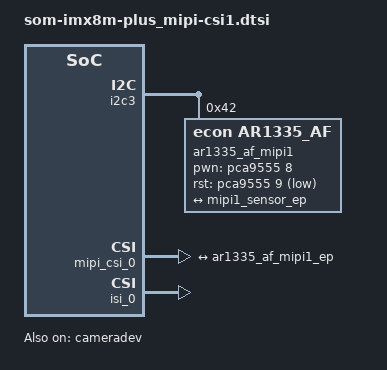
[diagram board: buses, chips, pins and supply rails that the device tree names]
/*
 * Copyright 2022 CompuLab
 */

&i2c3 {
	status = "okay";
	ar1335_af_mipi1: ar1335_af_mipi1@42 {
		compatible = "econ,ar1335_af", "ar1335_af";
		reg = <0x42>;
		pinctrl-names = "default";
		pinctrl-0 = <&pinctrl_csi_mclk>;
		clocks = <&clk IMX8MP_CLK_IPP_DO_CLKO2>;
		clock-names = "csi_mclk";
		assigned-clocks = <&clk IMX8MP_CLK_IPP_DO_CLKO2>;
		assigned-clock-parents = <&clk IMX8MP_CLK_24M>;
		assigned-clock-rates = <24000000>;
		csi_id = <0>;
		pwn-gpios = <&pca9555 8 GPIO_ACTIVE_HIGH>;
		rst-gpios = <&pca9555 9 GPIO_ACTIVE_LOW>;
		mclk = <24000000>;
		mclk_source = <0>;
		mipi_csi;
		status = "okay";

		port {
			ar1335_af_mipi1_ep: endpoint {
				data-lanes = <1 2 3 4>;
				clock-lanes = <0>;
				remote-endpoint = <&mipi1_sensor_ep>;
			};
		};
	};
};

&ar1335_af_mipi1 {
	status = "okay";
};

&mipi_csi_0 {
	status = "okay";
	port@0 {
		reg = <0>;
		mipi1_sensor_ep: endpoint@1 {
			remote-endpoint = <&ar1335_af_mipi1_ep>;
			data-lanes = <4>;
			csis-hs-settle = <23>;
			csis-clk-settle = <2>;
			csis-wclk;
		};
	};
};

&cameradev {
	status = "okay";
};

&isi_0 {
	status = "okay";
};
